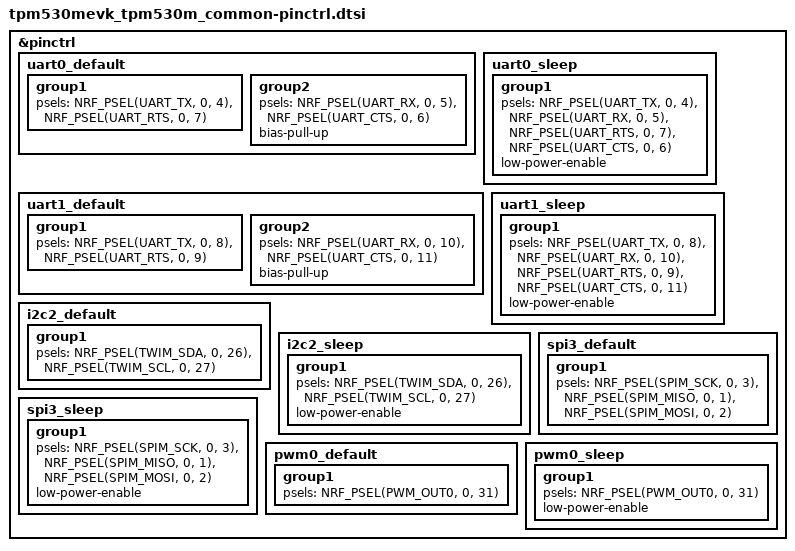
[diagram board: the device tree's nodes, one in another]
/*
 * Copyright (c) 2025 Nordic Semiconductor ASA
 * SPDX-License-Identifier: LicenseRef-Nordic-5-Clause
 */

&pinctrl {
	uart0_default: uart0_default {
		group1 {
			psels = <NRF_PSEL(UART_TX, 0, 4)>,
				<NRF_PSEL(UART_RTS, 0, 7)>;
		};

		group2 {
			psels = <NRF_PSEL(UART_RX, 0, 5)>,
				<NRF_PSEL(UART_CTS, 0, 6)>;
			bias-pull-up;
		};
	};

	uart0_sleep: uart0_sleep {
		group1 {
			psels = <NRF_PSEL(UART_TX, 0, 4)>,
				<NRF_PSEL(UART_RX, 0, 5)>,
				<NRF_PSEL(UART_RTS, 0, 7)>,
				<NRF_PSEL(UART_CTS, 0, 6)>;
			low-power-enable;
		};
	};

	uart1_default: uart1_default {
		group1 {
			psels = <NRF_PSEL(UART_TX, 0, 8)>,
				<NRF_PSEL(UART_RTS, 0, 9)>;
		};

		group2 {
			psels = <NRF_PSEL(UART_RX, 0, 10)>,
				<NRF_PSEL(UART_CTS, 0, 11)>;
			bias-pull-up;
		};
	};

	uart1_sleep: uart1_sleep {
		group1 {
			psels = <NRF_PSEL(UART_TX, 0, 8)>,
				<NRF_PSEL(UART_RX, 0, 10)>,
				<NRF_PSEL(UART_RTS, 0, 9)>,
				<NRF_PSEL(UART_CTS, 0, 11)>;
			low-power-enable;
		};
	};

	i2c2_default: i2c2_default {
		group1 {
			psels = <NRF_PSEL(TWIM_SDA, 0, 26)>,
				<NRF_PSEL(TWIM_SCL, 0, 27)>;
		};
	};

	i2c2_sleep: i2c2_sleep {
		group1 {
			psels = <NRF_PSEL(TWIM_SDA, 0, 26)>,
				<NRF_PSEL(TWIM_SCL, 0, 27)>;
			low-power-enable;
		};
	};

	spi3_default: spi3_default {
		group1 {
			psels = <NRF_PSEL(SPIM_SCK, 0, 3)>,
				<NRF_PSEL(SPIM_MISO, 0, 1)>,
				<NRF_PSEL(SPIM_MOSI, 0, 2)>;
		};
	};

	spi3_sleep: spi3_sleep {
		group1 {
			psels = <NRF_PSEL(SPIM_SCK, 0, 3)>,
				<NRF_PSEL(SPIM_MISO, 0, 1)>,
				<NRF_PSEL(SPIM_MOSI, 0, 2)>;
			low-power-enable;
		};
	};

	pwm0_default: pwm0_default {
		group1 {
			psels = <NRF_PSEL(PWM_OUT0, 0, 31)>;
		};
	};

	pwm0_sleep: pwm0_sleep {
		group1 {
			psels = <NRF_PSEL(PWM_OUT0, 0, 31)>;
			low-power-enable;
		};
	};
};
